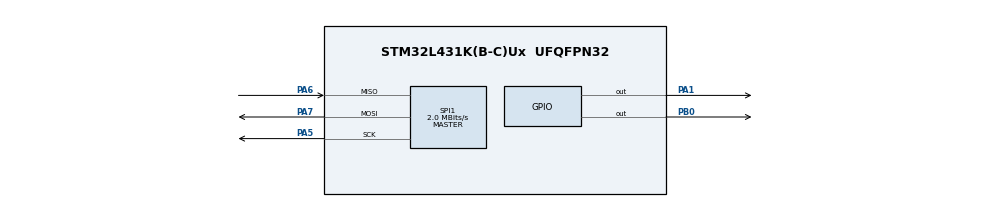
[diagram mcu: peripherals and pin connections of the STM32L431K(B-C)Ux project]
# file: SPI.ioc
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Mcu.Family=STM32L4
Mcu.Name=STM32L431K(B-C)Ux
Mcu.Package=UFQFPN32
NVIC.PriorityGroup=NVIC_PRIORITYGROUP_4
PA1.Signal=GPIO_Output
PA5.Mode=Full_Duplex_Master
PA5.Signal=SPI1_SCK
PA6.Mode=Full_Duplex_Master
PA6.Signal=SPI1_MISO
PA7.Mode=Full_Duplex_Master
PA7.Signal=SPI1_MOSI
PB0.Signal=GPIO_Output
ProjectManager.HeapSize=0x200
ProjectManager.StackSize=0x400
ProjectManager.TargetToolchain=STM32CubeIDE
RCC.HSE_VALUE=8000000
RCC.HSI48_VALUE=48000000
RCC.HSI_VALUE=16000000
RCC.LSE_VALUE=32768
RCC.MSI_VALUE=4000000
RCC.VCOOutputFreq_Value=32000000
SPI1.CalculateBaudRate=2.0 MBits/s
SPI1.Direction=SPI_DIRECTION_2LINES
SPI1.Mode=SPI_MODE_MASTER
SPI1.VirtualType=VM_MASTER
board=custom

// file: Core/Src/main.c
/* USER CODE BEGIN Header */
/**
  ******************************************************************************
  * @file           : main.c
  * @brief          : Main program body
  ******************************************************************************
  * @attention
  *
  * <h2><center>&copy; Copyright (c) 2024 STMicroelectronics.
  * All rights reserved.</center></h2>
  *
  * This software component is licensed by ST under BSD 3-Clause license,
  * the "License"; You may not use this file except in compliance with the
  * License. You may obtain a copy of the License at:
  *                        opensource.org/licenses/BSD-3-Clause
  *
  ******************************************************************************
  */
/* USER CODE END Header */
#include "main.h"

/* USER CODE BEGIN Includes */
#define FLASH_CS_Pin GPIO_PIN_15
#define FLASH_CS_GPIO_Port GPIOA
#define CMD_WRITE_ENABLE 0x06   // Enable write operations
#define CMD_PAGE_PROGRAM 0x02   // Program one page of data
#define CMD_READ_DATA 0x03   // Read data command
/* USER CODE END Includes */

SPI_HandleTypeDef hspi1;

void SystemClock_Config(void);
static void MX_GPIO_Init(void);
static void MX_SPI1_Init(void);

int main(void)
{

  /* MCU Configuration--------------------------------------------------------*/

  /* Reset of all peripherals, Initializes the Flash interface and the Systick. */
  HAL_Init();

  /* Configure the system clock */
  SystemClock_Config();

  /* USER CODE BEGIN SysInit */

  HAL_GPIO_WritePin(GPIOA, GPIO_PIN_1, SET);

  /* USER CODE END SysInit */

  /* Initialize all configured peripherals */
  MX_GPIO_Init();
  MX_SPI1_Init();

  /* Infinite loop */
  while (1)
  {

	  /* USER CODE BEGIN 3 */
	  // Example data to write
	  uint8_t data_to_write[] = "Hello, World!";
	  uint32_t address = 0x000000; // Address to write the data to

	  // Enable write operations
	  HAL_GPIO_WritePin(FLASH_CS_GPIO_Port, FLASH_CS_Pin, GPIO_PIN_RESET); // Select the flash chip
	  uint8_t cmd_enable_write = CMD_WRITE_ENABLE;
	  HAL_SPI_Transmit(&hspi1, &cmd_enable_write, 1, HAL_MAX_DELAY);
	  HAL_GPIO_WritePin(FLASH_CS_GPIO_Port, FLASH_CS_Pin, GPIO_PIN_SET); // Deselect the flash chip

	  HAL_Delay(10); // Small delay before next operation

	  // Write data to flash
	  HAL_GPIO_WritePin(FLASH_CS_GPIO_Port, FLASH_CS_Pin, GPIO_PIN_RESET); // Select the flash chip
	  uint8_t cmd_page_program = CMD_PAGE_PROGRAM;
	  HAL_SPI_Transmit(&hspi1, &cmd_page_program, 1, HAL_MAX_DELAY); // Send page program command

	  uint8_t address_bytes[3];
	  address_bytes[0] = (address >> 16) & 0xFF; // Most significant byte
	  address_bytes[1] = (address >> 8) & 0xFF;  // Mid byte
	  address_bytes[2] = address & 0xFF;         // Least significant byte
	  HAL_SPI_Transmit(&hspi1, address_bytes, 3, HAL_MAX_DELAY); // Send address

	  HAL_SPI_Transmit(&hspi1, data_to_write, sizeof(data_to_write), HAL_MAX_DELAY); // Send data

	  HAL_GPIO_WritePin(FLASH_CS_GPIO_Port, FLASH_CS_Pin, GPIO_PIN_SET); // Deselect the flash chip

	  // Wait for write operation to complete
	  HAL_Delay(10); // You may need to adjust the delay based on flash memory specifications

	  // Read data from flash
//	  HAL_GPIO_WritePin(FLASH_CS_GPIO_Port, FLASH_CS_Pin, GPIO_PIN_RESET); // Select the flash chip
//
//	  uint8_t cmd_read_data = CMD_READ_DATA;
//	  HAL_SPI_Transmit(&hspi1, &cmd_read_data, 1, HAL_MAX_DELAY); // Send read command
//
//	  HAL_SPI_Transmit(&hspi1, address_bytes, 3, HAL_MAX_DELAY); // Send address
//
//	  uint8_t read_data[20]; // Assuming a maximum of 20 bytes read
//	  HAL_SPI_Receive(&hspi1, read_data, sizeof(read_data), HAL_MAX_DELAY); // Receive data
//
//	  HAL_GPIO_WritePin(FLASH_CS_GPIO_Port, FLASH_CS_Pin, GPIO_PIN_SET); // Deselect the flash chip
//
//	  // Process the read data
//	  // You can use the read_data array for further processing
  }
}

void SystemClock_Config(void)
{
  RCC_OscInitTypeDef RCC_OscInitStruct = {0};
  RCC_ClkInitTypeDef RCC_ClkInitStruct = {0};

  /** Configure the main internal regulator output voltage
  */
  if (HAL_PWREx_ControlVoltageScaling(PWR_REGULATOR_VOLTAGE_SCALE1) != HAL_OK)
  {
    Error_Handler();
  }
  /** Initializes the RCC Oscillators according to the specified parameters
  * in the RCC_OscInitTypeDef structure.
  */
  RCC_OscInitStruct.OscillatorType = RCC_OSCILLATORTYPE_MSI;
  RCC_OscInitStruct.MSIState = RCC_MSI_ON;
  RCC_OscInitStruct.MSICalibrationValue = 0;
  RCC_OscInitStruct.MSIClockRange = RCC_MSIRANGE_6;
  RCC_OscInitStruct.PLL.PLLState = RCC_PLL_NONE;
  if (HAL_RCC_OscConfig(&RCC_OscInitStruct) != HAL_OK)
  {
    Error_Handler();
  }
  /** Initializes the CPU, AHB and APB buses clocks
  */
  RCC_ClkInitStruct.ClockType = RCC_CLOCKTYPE_HCLK|RCC_CLOCKTYPE_SYSCLK
                              |RCC_CLOCKTYPE_PCLK1|RCC_CLOCKTYPE_PCLK2;
  RCC_ClkInitStruct.SYSCLKSource = RCC_SYSCLKSOURCE_MSI;
  RCC_ClkInitStruct.AHBCLKDivider = RCC_SYSCLK_DIV1;
  RCC_ClkInitStruct.APB1CLKDivider = RCC_HCLK_DIV1;
  RCC_ClkInitStruct.APB2CLKDivider = RCC_HCLK_DIV1;

  if (HAL_RCC_ClockConfig(&RCC_ClkInitStruct, FLASH_LATENCY_0) != HAL_OK)
  {
    Error_Handler();
  }
}

static void MX_SPI1_Init(void)
{

  /* SPI1 parameter configuration*/
  hspi1.Instance = SPI1;
  hspi1.Init.Mode = SPI_MODE_MASTER;
  hspi1.Init.Direction = SPI_DIRECTION_2LINES;
  hspi1.Init.DataSize = SPI_DATASIZE_4BIT;
  hspi1.Init.CLKPolarity = SPI_POLARITY_LOW;
  hspi1.Init.CLKPhase = SPI_PHASE_1EDGE;
  hspi1.Init.NSS = SPI_NSS_SOFT;
  hspi1.Init.BaudRatePrescaler = SPI_BAUDRATEPRESCALER_2;
  hspi1.Init.FirstBit = SPI_FIRSTBIT_MSB;
  hspi1.Init.TIMode = SPI_TIMODE_DISABLE;
  hspi1.Init.CRCCalculation = SPI_CRCCALCULATION_DISABLE;
  hspi1.Init.CRCPolynomial = 7;
  hspi1.Init.CRCLength = SPI_CRC_LENGTH_DATASIZE;
  hspi1.Init.NSSPMode = SPI_NSS_PULSE_ENABLE;
  if (HAL_SPI_Init(&hspi1) != HAL_OK)
  {
    Error_Handler();
  }

}

static void MX_GPIO_Init(void)
{
  GPIO_InitTypeDef GPIO_InitStruct = {0};

  /* GPIO Ports Clock Enable */
  __HAL_RCC_GPIOA_CLK_ENABLE();
  __HAL_RCC_GPIOB_CLK_ENABLE();

  /*Configure GPIO pin Output Level */
  HAL_GPIO_WritePin(GPIOB, GPIO_PIN_0, GPIO_PIN_RESET);

  /*Configure GPIO pin : PB0 */
  GPIO_InitStruct.Pin = GPIO_PIN_0;
  GPIO_InitStruct.Mode = GPIO_MODE_OUTPUT_PP;
  GPIO_InitStruct.Pull = GPIO_NOPULL;
  GPIO_InitStruct.Speed = GPIO_SPEED_FREQ_LOW;
  HAL_GPIO_Init(GPIOB, &GPIO_InitStruct);

}

void Error_Handler(void)
{
  __disable_irq();
  while (1)
  {
  }
}

/************************ (C) COPYRIGHT STMicroelectronics *****END OF FILE****/
